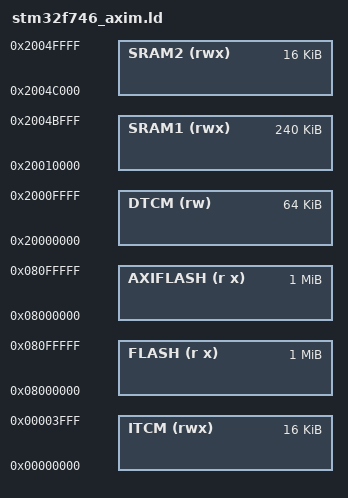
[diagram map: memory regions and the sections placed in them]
MEMORY
{
	ITCM     (rwx) : ORIGIN = 0x00000000, LENGTH = 16K
	FLASH    (r x) : ORIGIN = 0x08000000, LENGTH = 1024K
	AXIFLASH (r x) : ORIGIN = 0x08000000, LENGTH = 1024K
	DTCM     (rw ) : ORIGIN = 0x20000000, LENGTH = 64K
	SRAM1    (rwx) : ORIGIN = 0x20010000, LENGTH = 240K
	SRAM2    (rwx) : ORIGIN = 0x2004C000, LENGTH = 16K
}

INCLUDE "stm32f7xx_common.ld"
